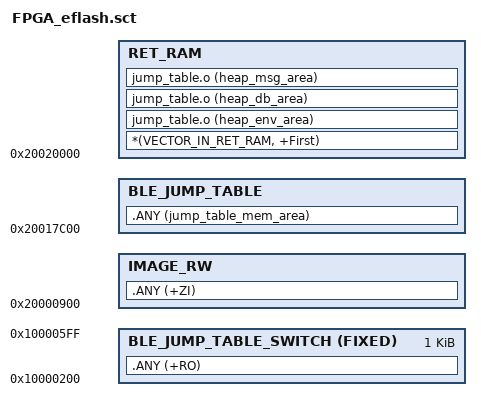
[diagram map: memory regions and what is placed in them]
; *************************************************************
; *** Scatter-Loading Description File generated by uVision ***
; *************************************************************

SOC 0x10000000 0x10000  ; 64KB
{
    STARTUP + 0
    {
        *(VECTOR_IN_EFLASH, +First)
        *(InRoot$$Sections)
    }

    ;BLE_JUMP_TABLE 0x10000200 FIXED 0x400
    ;{
    ;    .ANY (jump_table_mem_area)
    ;}

    BLE_JUMP_TABLE_SWITCH 0x10000200 FIXED 0x400
    {
        .ANY (jump_table_switch_mem_area)
    }
    
    IMAGE_RO + 0
    {
        .ANY (+RO)
    }

    IMAGE_RW 0x20000900      ; fixed address after BootROM BLE_ZI
    {
        *(RO_IN_SYS_RAM)
        ;*(RW_IN_SYS_RAM)
        ;clock.o (+RO, +RW, +ZI)
        .ANY (+RW)
    }

    IMAGE_ZI + 0
    {
        ;*(ZI_IN_SYS_RAM)
        .ANY (+ZI)
    }

    BLE_JUMP_TABLE 0x20017C00 
    {
        .ANY (jump_table_mem_area)
    }
    
    RET_RAM 0x20020000 ; Retention memory
    {
        *(VECTOR_IN_RET_RAM, +First)
        ;*(IN_RET_RAM)
        jump_table.o (heap_env_area)
        jump_table.o (heap_db_area)
        jump_table.o (heap_msg_area)
    }

}

